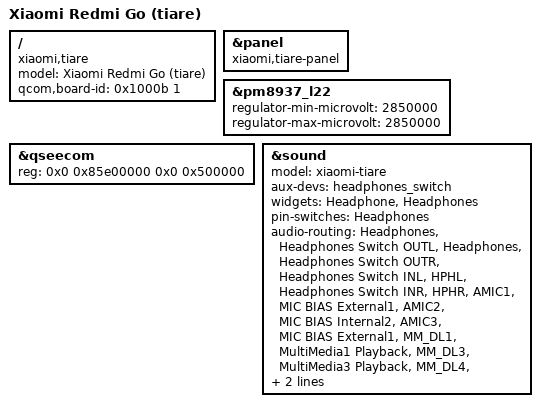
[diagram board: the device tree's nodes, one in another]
// SPDX-License-Identifier: GPL-2.0-only
/*
 * Copyright (c) 2026, Barnabas Czeman
 */

/dts-v1/;

#include "msm8917-xiaomi-wingtech.dtsi"

/ {
	model = "Xiaomi Redmi Go (tiare)";
	compatible = "xiaomi,tiare", "qcom,msm8917";

	qcom,board-id = <0x1000b 1>;
};

&panel {
	compatible = "xiaomi,tiare-panel";
};

&pm8937_l22 {
	regulator-min-microvolt = <2850000>;
	regulator-max-microvolt = <2850000>;
};

/* Unlike riva and rolex, the secure app region is smaller and moved up. */
&qseecom {
	reg = <0x0 0x85e00000 0x0 0x500000>;
};

&sound {
	model = "xiaomi-tiare";

	aux-devs = <&headphones_switch>;
	widgets =
		"Headphone", "Headphones";
	pin-switches = "Headphones";
	audio-routing =
		"Headphones", "Headphones Switch OUTL",
		"Headphones", "Headphones Switch OUTR",
		"Headphones Switch INL", "HPHL",
		"Headphones Switch INR", "HPHR",
		"AMIC1", "MIC BIAS External1",
		"AMIC2", "MIC BIAS Internal2",
		"AMIC3", "MIC BIAS External1",
		"MM_DL1", "MultiMedia1 Playback",
		"MM_DL3", "MultiMedia3 Playback",
		"MM_DL4", "MultiMedia4 Playback",
		"MultiMedia2 Capture", "MM_UL2";
};
